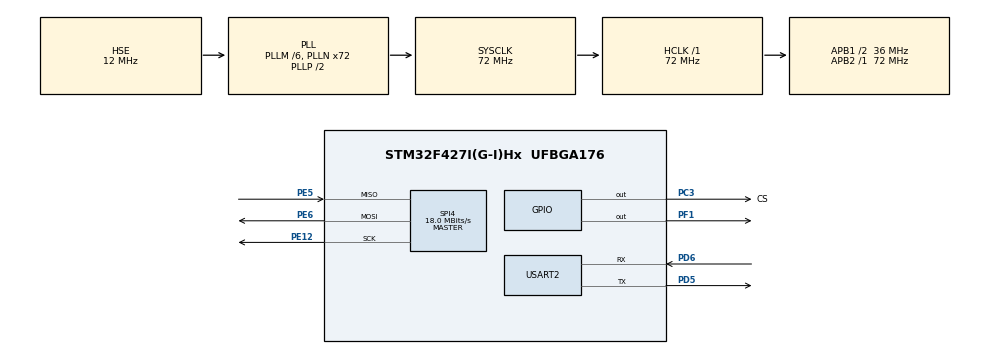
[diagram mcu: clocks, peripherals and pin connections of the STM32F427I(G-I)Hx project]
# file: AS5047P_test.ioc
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Mcu.Family=STM32F4
Mcu.Name=STM32F427I(G-I)Hx
Mcu.Package=UFBGA176
NVIC.PriorityGroup=NVIC_PRIORITYGROUP_4
NVIC.SPI4_IRQn=true\:0\:0\:false\:false\:true\:true\:true\:true
NVIC.TIM1_UP_TIM10_IRQn=true\:15\:0\:false\:false\:true\:false\:true\:true
NVIC.TimeBase=TIM1_UP_TIM10_IRQn
NVIC.TimeBaseIP=TIM1
PA13.Mode=Serial_Wire
PA13.Signal=SYS_JTMS-SWDIO
PA14.Mode=Serial_Wire
PA14.Signal=SYS_JTCK-SWCLK
PC3.GPIO_Label=CS
PC3.GPIO_PuPd=GPIO_PULLUP
PC3.GPIO_Speed=GPIO_SPEED_FREQ_HIGH
PC3.PinState=GPIO_PIN_SET
PC3.Signal=GPIO_Output
PD5.Mode=Asynchronous
PD5.Signal=USART2_TX
PD6.Mode=Asynchronous
PD6.Signal=USART2_RX
PE12.Mode=Full_Duplex_Master
PE12.Signal=SPI4_SCK
PE5.Mode=Full_Duplex_Master
PE5.Signal=SPI4_MISO
PE6.Mode=Full_Duplex_Master
PE6.Signal=SPI4_MOSI
PF1.GPIO_PuPd=GPIO_PULLUP
PF1.GPIO_Speed=GPIO_SPEED_FREQ_VERY_HIGH
PF1.PinState=GPIO_PIN_SET
PF1.Signal=GPIO_Output
PH0/OSC_IN.Mode=HSE-External-Oscillator
PH0/OSC_IN.Signal=RCC_OSC_IN
PH1/OSC_OUT.Mode=HSE-External-Oscillator
PH1/OSC_OUT.Signal=RCC_OSC_OUT
ProjectManager.HeapSize=0x200
ProjectManager.StackSize=0x400
ProjectManager.TargetToolchain=MDK-ARM V5.32
RCC.48MHZClocksFreq_Value=36000000
RCC.AHBFreq_Value=72000000
RCC.APB1CLKDivider=RCC_HCLK_DIV2
RCC.APB1Freq_Value=36000000
RCC.APB1TimFreq_Value=72000000
RCC.APB2Freq_Value=72000000
RCC.APB2TimFreq_Value=72000000
RCC.CortexFreq_Value=72000000
RCC.HCLKFreq_Value=72000000
RCC.HSE_VALUE=12000000
RCC.HSI_VALUE=16000000
RCC.LSE_VALUE=32768
RCC.PLLM=6
RCC.PLLN=72
RCC.PLLSourceVirtual=RCC_PLLSOURCE_HSE
RCC.SYSCLKFreq_VALUE=72000000
RCC.SYSCLKSource=RCC_SYSCLKSOURCE_PLLCLK
RCC.VCOOutputFreq_Value=144000000
SPI4.BaudRatePrescaler=SPI_BAUDRATEPRESCALER_4
SPI4.CLKPhase=SPI_PHASE_2EDGE
SPI4.CLKPolarity=SPI_POLARITY_LOW
SPI4.CRCCalculation=SPI_CRCCALCULATION_DISABLE
SPI4.CalculateBaudRate=18.0 MBits/s
SPI4.DataSize=SPI_DATASIZE_16BIT
SPI4.Direction=SPI_DIRECTION_2LINES
SPI4.Mode=SPI_MODE_MASTER
SPI4.VirtualType=VM_MASTER
USART2.VirtualMode=VM_ASYNC
VP_SYS_VS_tim1.Mode=TIM1
board=custom

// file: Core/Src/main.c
/* USER CODE BEGIN Header */
/**
  ******************************************************************************
  * @file           : main.c
  * @brief          : Main program body
  ******************************************************************************
  * @attention
  *
  * Copyright (c) 2024 STMicroelectronics.
  * All rights reserved.
  *
  * This software is licensed under terms that can be found in the LICENSE file
  * in the root directory of this software component.
  * If no LICENSE file comes with this software, it is provided AS-IS.
  *
  ******************************************************************************
  */
/* USER CODE END Header */
#include "main.h"
#include "spi.h"
#include "usart.h"
#include "gpio.h"

/* USER CODE BEGIN Includes */
#include "as5047p.h"
#include "Vofa_firewater.h"
/* USER CODE END Includes */

/* USER CODE BEGIN PV */
//uint16_t a,b;
uint16_t angle;
uint16_t AA;
/* USER CODE END PV */

void SystemClock_Config(void);

int main(void)
{

  /* MCU Configuration--------------------------------------------------------*/

  /* Reset of all peripherals, Initializes the Flash interface and the Systick. */
  HAL_Init();

  /* Configure the system clock */
  SystemClock_Config();

  /* Initialize all configured peripherals */
  MX_GPIO_Init();
  MX_SPI4_Init();
  MX_USART2_UART_Init();

  /* Infinite loop */
  /* USER CODE BEGIN WHILE */
	HAL_Delay(1000);
  while (1)
  {
		angle=AS5047_read(ANGLEUNC);
		firewater_task();
		HAL_Delay(5);
//		a=ReadRegister(0xFFFC)&0x0fff;     //AGC=>bit11:MAGL,bit10:MAGH,bit7-0:AGC   0x01AD
//		b=((float)(ReadRegister(0xFFFF)&0x3fff)*360)/16384;   //angle
    /* USER CODE END WHILE */

  }
}

void SystemClock_Config(void)
{
  RCC_OscInitTypeDef RCC_OscInitStruct = {0};
  RCC_ClkInitTypeDef RCC_ClkInitStruct = {0};

  /** Configure the main internal regulator output voltage
  */
  __HAL_RCC_PWR_CLK_ENABLE();
  __HAL_PWR_VOLTAGESCALING_CONFIG(PWR_REGULATOR_VOLTAGE_SCALE3);

  /** Initializes the RCC Oscillators according to the specified parameters
  * in the RCC_OscInitTypeDef structure.
  */
  RCC_OscInitStruct.OscillatorType = RCC_OSCILLATORTYPE_HSE;
  RCC_OscInitStruct.HSEState = RCC_HSE_ON;
  RCC_OscInitStruct.PLL.PLLState = RCC_PLL_ON;
  RCC_OscInitStruct.PLL.PLLSource = RCC_PLLSOURCE_HSE;
  RCC_OscInitStruct.PLL.PLLM = 6;
  RCC_OscInitStruct.PLL.PLLN = 72;
  RCC_OscInitStruct.PLL.PLLP = RCC_PLLP_DIV2;
  RCC_OscInitStruct.PLL.PLLQ = 4;
  if (HAL_RCC_OscConfig(&RCC_OscInitStruct) != HAL_OK)
  {
    Error_Handler();
  }

  /** Initializes the CPU, AHB and APB buses clocks
  */
  RCC_ClkInitStruct.ClockType = RCC_CLOCKTYPE_HCLK|RCC_CLOCKTYPE_SYSCLK
                              |RCC_CLOCKTYPE_PCLK1|RCC_CLOCKTYPE_PCLK2;
  RCC_ClkInitStruct.SYSCLKSource = RCC_SYSCLKSOURCE_PLLCLK;
  RCC_ClkInitStruct.AHBCLKDivider = RCC_SYSCLK_DIV1;
  RCC_ClkInitStruct.APB1CLKDivider = RCC_HCLK_DIV2;
  RCC_ClkInitStruct.APB2CLKDivider = RCC_HCLK_DIV1;

  if (HAL_RCC_ClockConfig(&RCC_ClkInitStruct, FLASH_LATENCY_2) != HAL_OK)
  {
    Error_Handler();
  }
}

void HAL_TIM_PeriodElapsedCallback(TIM_HandleTypeDef *htim)
{
  if (htim->Instance == TIM1) {
    HAL_IncTick();
  }
}

void Error_Handler(void)
{
  __disable_irq();
  while (1)
  {
  }
}
